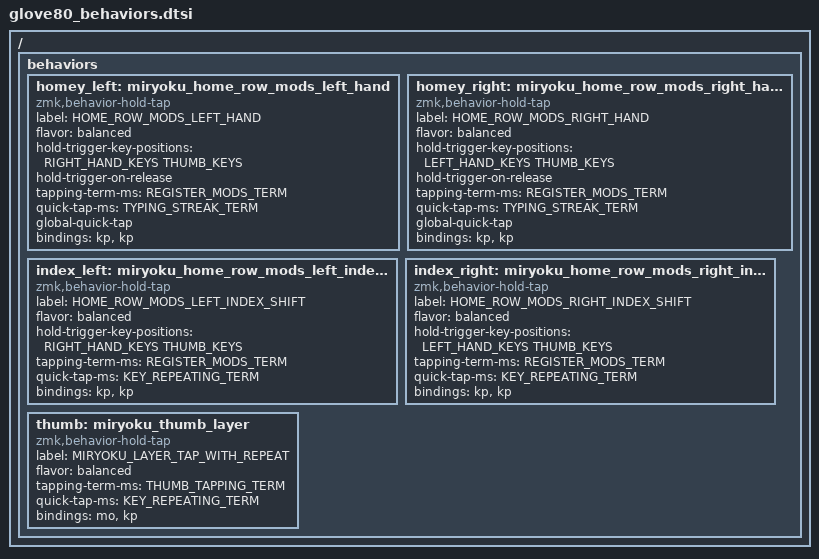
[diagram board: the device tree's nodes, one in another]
/* Glove80 specific key positions */
#define LEFT_HAND_KEYS      \
          0  1  2  3  4         \
         10 11 12 13 14 15      \
         22 23 24 25 26 27      \
         34 35 36 37 38 39      \
         46 47 48 49 50 51      \
         64 65 66 67 68

#define RIGHT_HAND_KEYS     \
                                           5  6  7  8  9 \
                                       16 17 18 19 20 21 \
                                       28 29 30 31 32 33 \
                                       40 41 42 43 44 45 \
                                       58 59 60 61 62 63 \
                                          75 76 77 78 79

#define THUMB_KEYS          \
                        69 52       57 74                \
                         70 53     56 73                 \
                          71 54   55 72

/ {
    behaviors {
        // Glove80-specific home row mods
        homey_left: miryoku_home_row_mods_left_hand {
            compatible = "zmk,behavior-hold-tap";
            label = "HOME_ROW_MODS_LEFT_HAND";
            flavor = "balanced";
            hold-trigger-key-positions = <RIGHT_HAND_KEYS THUMB_KEYS>;
            hold-trigger-on-release;
            tapping-term-ms = <REGISTER_MODS_TERM>;
            quick-tap-ms = <TYPING_STREAK_TERM>;
            global-quick-tap;
            #binding-cells = <2>;
            bindings = <&kp>, <&kp>;
        };

        homey_right: miryoku_home_row_mods_right_hand {
            compatible = "zmk,behavior-hold-tap";
            label = "HOME_ROW_MODS_RIGHT_HAND";
            flavor = "balanced";
            hold-trigger-key-positions = <LEFT_HAND_KEYS THUMB_KEYS>;
            hold-trigger-on-release;
            tapping-term-ms = <REGISTER_MODS_TERM>;
            quick-tap-ms = <TYPING_STREAK_TERM>;
            global-quick-tap;
            #binding-cells = <2>;
            bindings = <&kp>, <&kp>;
        };

        index_left: miryoku_home_row_mods_left_index_shift {
            compatible = "zmk,behavior-hold-tap";
            label = "HOME_ROW_MODS_LEFT_INDEX_SHIFT";
            flavor = "balanced";
            hold-trigger-key-positions = <RIGHT_HAND_KEYS THUMB_KEYS>;
            tapping-term-ms = <REGISTER_MODS_TERM>;
            quick-tap-ms = <KEY_REPEATING_TERM>;
            #binding-cells = <2>;
            bindings = <&kp>, <&kp>;
        };

        index_right: miryoku_home_row_mods_right_index_shift {
            compatible = "zmk,behavior-hold-tap";
            label = "HOME_ROW_MODS_RIGHT_INDEX_SHIFT";
            flavor = "balanced";
            hold-trigger-key-positions = <LEFT_HAND_KEYS THUMB_KEYS>;
            tapping-term-ms = <REGISTER_MODS_TERM>;
            quick-tap-ms = <KEY_REPEATING_TERM>;
            #binding-cells = <2>;
            bindings = <&kp>, <&kp>;
        };

        thumb: miryoku_thumb_layer {
            compatible = "zmk,behavior-hold-tap";
            label = "MIRYOKU_LAYER_TAP_WITH_REPEAT";
            flavor = "balanced";
            tapping-term-ms = <THUMB_TAPPING_TERM>;
            quick-tap-ms = <KEY_REPEATING_TERM>;
            #binding-cells = <2>;
            bindings = <&mo>, <&kp>;
        };
    };
}; 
